# EFM32GG11B420F2048IL112 register map
File version: 4.0.0
CPU: CM4 r0p1, little endian, MPU, FPU, 3 interrupt priority bits
Registers are 32-bit, read-write, reset 0x0 unless marked. A register's access mark holds for its fields unless they carry their own. Offsets are from the block's base; [hi:lo] are bit positions; {n}, {i} and the like mark numbered series; 'fields as' and 'values as' point back to an identical list.

## EBI
Base 0x4000B000
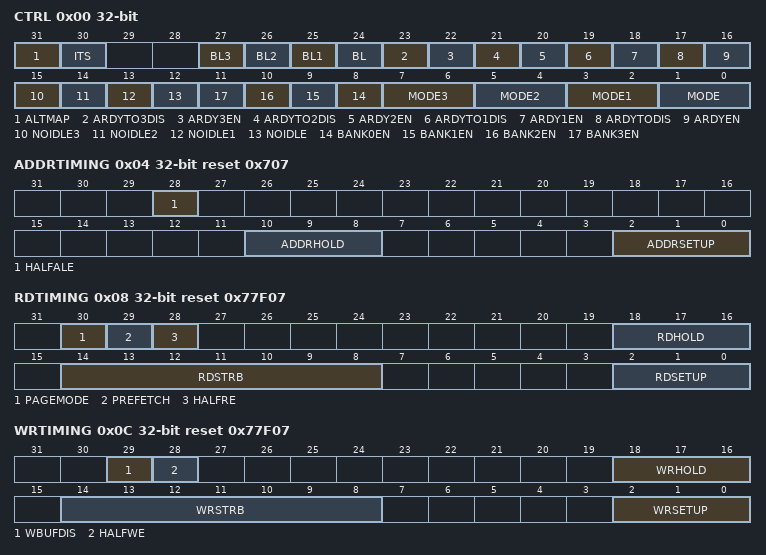
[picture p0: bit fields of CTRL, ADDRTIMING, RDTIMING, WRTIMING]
0x00 CTRL — Control Register
  [31] ALTMAP — Alternative Address Map Enable
  [30] ITS — Individual Timing Set, Line Polarity and Mode Definition Enable
  [27] BL3 — Byte Lane Enable for Bank 3
  [26] BL2 — Byte Lane Enable for Bank 2
  [25] BL1 — Byte Lane Enable for Bank 1
  [24] BL — Byte Lane Enable for Bank 0
  [23] ARDYTO3DIS — ARDY Timeout Disable for Bank 3
  [22] ARDY3EN — ARDY Enable for Bank 3
  [21] ARDYTO2DIS — ARDY Timeout Disable for Bank 2
  [20] ARDY2EN — ARDY Enable for Bank 2
  [19] ARDYTO1DIS — ARDY Timeout Disable for Bank 1
  [18] ARDY1EN — ARDY Enable for Bank 1
  [17] ARDYTODIS — ARDY Timeout Disable
  [16] ARDYEN — ARDY Enable
  [15] NOIDLE3 — No Idle Cycle Insertion on Bank 3
  [14] NOIDLE2 — No Idle Cycle Insertion on Bank 2
  [13] NOIDLE1 — No Idle Cycle Insertion on Bank 1
  [12] NOIDLE — No Idle Cycle Insertion on Bank 0
  [n+8] BANK{n}EN (n=0..3) — Bank {n} Enable
  [7:6] MODE3
    0=D8A8 (EBI_AD drives 8 bit data, 8 bit address, ALE not used. Extended address bits can be enabled.); 1=D16A16ALE (EBI_AD drives 16 bit data, 16 bit address, ALE is used for address latching. Extended address bits can be enabled.); 2=D8A24ALE (EBI_AD drives 8 bit data, 24 bit address, ALE is used for address latching. Extended address bits can be enabled.); 3=D16 (EBI_AD drives 16 bit data, ALE not used. Extended address bits can be enabled.)
  [5:4] MODE2
    values as MODE3
  [3:2] MODE1
    values as MODE3
  [1:0] MODE
    values as MODE3
0x04 ADDRTIMING reset 0x707 — Address Timing Register
  [28] HALFALE — Half Cycle ALE Strobe Duration Enable
  [10:8] ADDRHOLD — Address Hold Time
  [2:0] ADDRSETUP — Address Setup Time
0x08 RDTIMING reset 0x77F07 — Read Timing Register
  [30] PAGEMODE — Page Mode Access Enable
  [29] PREFETCH — Prefetch Enable
  [28] HALFRE — Half Cycle REn Strobe Duration Enable
  [18:16] RDHOLD — Read Hold Time
  [14:8] RDSTRB — Read Strobe Time
  [2:0] RDSETUP — Read Setup Time
0x0C WRTIMING reset 0x77F07 — Write Timing Register
  [29] WBUFDIS — Write Buffer Disable
  [28] HALFWE — Half Cycle WEn Strobe Duration Enable
  [18:16] WRHOLD — Write Hold Time
  [14:8] WRSTRB — Write Strobe Time
  [2:0] WRSETUP — Write Setup Time
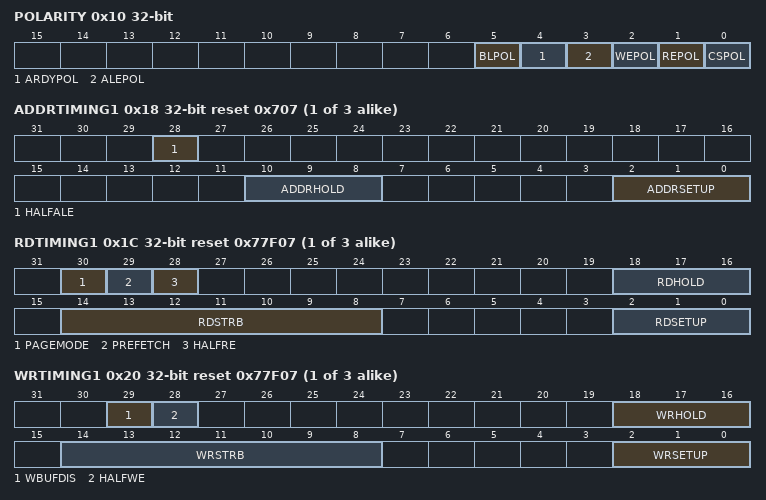
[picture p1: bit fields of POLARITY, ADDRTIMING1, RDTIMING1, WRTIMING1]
0x10 POLARITY
  [5] BLPOL — BL Polarity
  [4] ARDYPOL — ARDY Polarity
  [3] ALEPOL — Address Latch Polarity
  [2] WEPOL — Write Enable Polarity
  [1] REPOL — Read Enable Polarity
  [0] CSPOL — Chip Select Polarity
{0x8+0x10*i} ADDRTIMING{i} reset 0x707 (i=1..3) — Address Timing Register {i}
  fields as ADDRTIMING
{0xC+0x10*i} RDTIMING{i} reset 0x77F07 (i=1..3) — Read Timing Register {i}
  fields as RDTIMING
{0x10+0x10*i} WRTIMING{i} reset 0x77F07 (i=1..3) — Write Timing Register {i}
  fields as WRTIMING
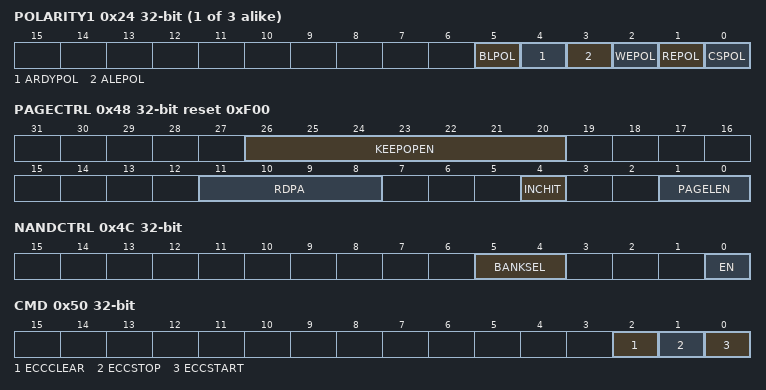
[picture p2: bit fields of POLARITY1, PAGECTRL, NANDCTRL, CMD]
{0x14+0x10*i} POLARITY{i} (i=1..3) — Polarity Register {i}
  fields as POLARITY
0x48 PAGECTRL reset 0xF00 — Page Control Register
  [26:20] KEEPOPEN — Maximum Page Open Time
  [11:8] RDPA — Page Read Access Time
  [4] INCHIT — Intrapage Hit Only on Incremental Addresses
  [1:0] PAGELEN — Page Length
    0=MEMBER4 (4 members in a page.); 1=MEMBER8 (8 members in a page.); 2=MEMBER16 (16 members in a page.); 3=MEMBER32 (32 members in a page.)
0x4C NANDCTRL — NAND Control Register
  [5:4] BANKSEL — NAND Flash Bank
    {v}=BANK{v} (Memory bank {v} is connected to a NAND Flash device.) (v=0..3)
  [0] EN — NAND Flash Control Enable
0x50 CMD wo — Command Register
  [2] ECCCLEAR — Error Correction Code Clear
  [1] ECCSTOP — Error Correction Code Generation Stop
  [0] ECCSTART — Error Correction Code Generation Start
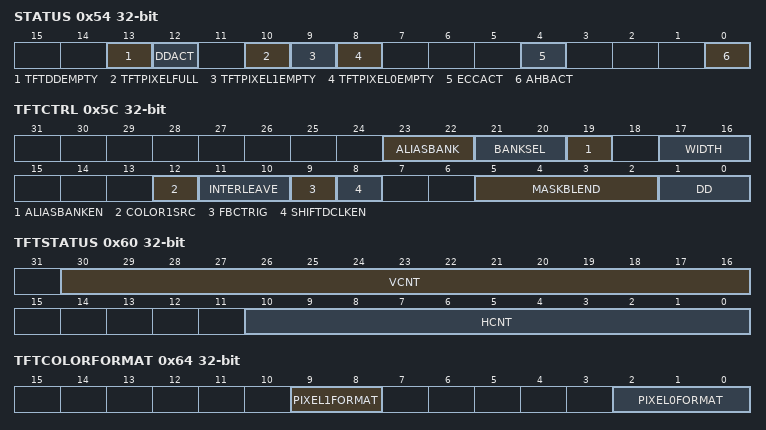
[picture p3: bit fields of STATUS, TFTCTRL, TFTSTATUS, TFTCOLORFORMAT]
0x54 STATUS ro
  [13] TFTDDEMPTY — EBI_TFTDD Register is Empty
  [12] DDACT — EBI Busy With Direct Drive Transactions
  [10] TFTPIXELFULL — EBI_TFTPIXEL0 is Full
  [9] TFTPIXEL1EMPTY — EBI_TFTPIXEL1 is Empty
  [8] TFTPIXEL0EMPTY — EBI_TFTPIXEL0 is Empty
  [4] ECCACT — EBI ECC Generation Active
  [0] AHBACT — EBI Busy With AHB Transaction
0x58 ECCPARITY ro
  [31:0] ECCPARITY — ECC Parity Data
0x5C TFTCTRL — TFT Control Register
  [23:22] ALIASBANK — Graphic Bank Select Aliasing
    {v}=Graphic Bank Select is alias to Bank Select {v} (v=0..3)
  [21:20] BANKSEL — Graphics Bank
    {v}=BANK{v} (Memory bank {v} is used for Direct Drive, Masking, and Alpha Blending.) (v=0..3)
  [19] ALIASBANKEN — Alias to Graphics Bank Enable
  [17:16] WIDTH — TFT Transaction Width
    0=BYTE (TFT Data is 8 bit wide.); 1=HALFWORD (TFT Data is 16 bit wide.)
  [12] COLOR1SRC — Masking/Alpha Blending Color1 Source
  [11:10] INTERLEAVE — Interleave Mode
    0=UNLIMITED (Allow unlimited interleaved EBI accesses per EBI_DCLK period. This can cause jitter on the EBI_DCLK); 1=ONEPERDCLK (Allow 1 interleaved EBI access per EBI_DCLK period.); 2=PORCH (Only allow EBI accesses during TFT porches.)
  [9] FBCTRIG — TFT Frame Base Copy Trigger
  [8] SHIFTDCLKEN — TFT EBI_DCLK Shift Enable
  [5:2] MASKBLEND — TFT Mask and Blend Mode
    0=DISABLED (Masking and Blending are disabled.); 1=IMASK (Internal Masking is enabled.); 2=IALPHA (Internal Alpha Blending is enabled.); 3=IMASKALPHA (Internal Masking and Alpha Blending are enabled.); 4=EFBMASK (External Frame Buffer Masking is enabled.); 5=EFBALPHA (External Frame Buffer Alpha Blending is enabled.); 6=EFBMASKALPHA (External Frame Buffer Masking and Alpha Blending are enabled.); 7=IFBMASK (Internal Frame Buffer Masking is enabled.); 8=IFBALPHA (Internal Frame Buffer Alpha Blending is enabled.); 9=IFBMASKALPHA (Internal Frame Buffer Masking and Alpha Blending are enabled.)
  [1:0] DD — TFT Direct Drive Mode
    0=DISABLED (Direct Drive is disabled.); 1=INTERNAL (Direct Drive from internal memory enabled and started.); 2=EXTERNAL (Direct Drive from external memory enabled and started.)
0x60 TFTSTATUS ro
  [30:16] VCNT — Vertical Count
  [10:0] HCNT — Horizontal Count
0x64 TFTCOLORFORMAT — Color Format Register
  [9:8] PIXEL1FORMAT — Source and Destination Pixel Color Format
    0=RGB555 (RGB data is 555); 1=RGB565 (RGB data is 565); 2=RGB666 (RGB data is 666); 3=RGB888 (RGB data is 888)
  [2:0] PIXEL0FORMAT — Sprite Pixel Color Format
    0=ARGB0555 (ARGB data is 0555); 1=ARGB0565 (ARGB data is 0565); 2=ARGB0666 (ARGB data is 0666); 3=ARGB0888 (ARGB data is 0888); 4=ARGB5555 (ARGB data is 5555); 5=ARGB6565 (ARGB data is 6565); 6=ARGB6666 (ARGB data is 6666); 7=ARGB8888 (ARGB data is 8888)
0x68 TFTFRAMEBASE
  [27:0] FRAMEBASE — Frame Base Address
0x70 TFTSTRIDE
  [11:0] HSTRIDE — Horizontal Stride
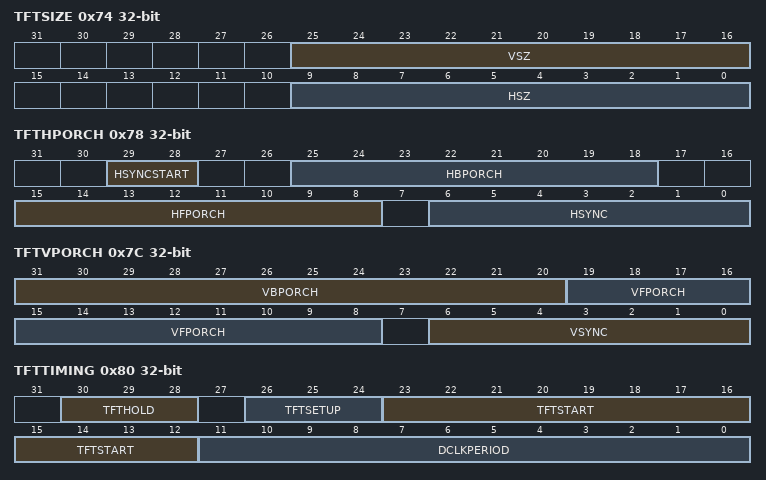
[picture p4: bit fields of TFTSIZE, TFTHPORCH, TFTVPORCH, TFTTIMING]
0x74 TFTSIZE
  [25:16] VSZ — Vertical Size (excluding Porches)
  [9:0] HSZ — Horizontal Size (excluding Porches)
0x78 TFTHPORCH — TFT Horizontal Porch Register
  [29:28] HSYNCSTART — HSYNC Start Delay
  [25:18] HBPORCH — Horizontal Back Porch Size
  [15:8] HFPORCH — Horizontal Front Porch Size
  [6:0] HSYNC — Horizontal Synchronization Pulse Width
0x7C TFTVPORCH — TFT Vertical Porch Register
  [31:20] VBPORCH — Vertical Back Porch Size
  [19:8] VFPORCH — Vertical Front Porch Size
  [6:0] VSYNC — Vertical Synchronization Pulse Width
0x80 TFTTIMING
  [30:28] TFTHOLD — TFT Hold Time
  [26:24] TFTSETUP — TFT Setup Time
  [23:12] TFTSTART — TFT Direct Drive Transaction Start
  [11:0] DCLKPERIOD — TFT Direct Drive Transaction (EBI_DCLK) Period
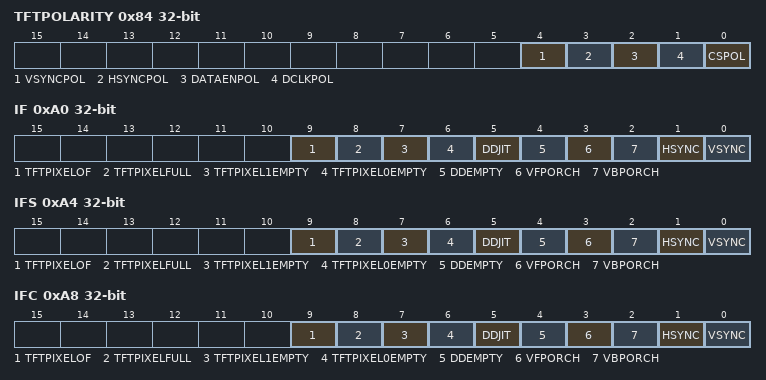
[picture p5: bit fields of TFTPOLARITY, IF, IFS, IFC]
0x84 TFTPOLARITY
  [4] VSYNCPOL — VSYNC Polarity
  [3] HSYNCPOL — Address Latch Polarity
  [2] DATAENPOL — TFT DATAEN Polarity
  [1] DCLKPOL — TFT DCLK Polarity
  [0] CSPOL — TFT Chip Select Polarity
0x88 TFTDD — TFT Direct Drive Data Register
  [23:0] DATA — TFT Direct Drive Data From Internal Memory
0x8C TFTALPHA — TFT Alpha Blending Register
  [8:0] ALPHA — TFT Alpha Blending Factor
0x90 TFTPIXEL0
  [23:0] DATA — RGB Data
0x94 TFTPIXEL1
  [23:0] DATA — RGB Data
0x98 TFTPIXEL ro — TFT Alpha Blending Result Pixel Register
  [23:0] DATA — Alpha Blending Result
0x9C TFTMASK — TFT Masking Register
  [23:0] TFTMASK — TFT Mask Value
0xA0 IF ro — Interrupt Flag Register
  [9] TFTPIXELOF — EBI_TFTPIXEL Register Overflow Interrupt Flag
  [8] TFTPIXELFULL — EBI_TFTPIXEL is Full Interrupt Flag
  [7] TFTPIXEL1EMPTY — EBI_TFTPIXEL1 is Empty Interrupt Flag
  [6] TFTPIXEL0EMPTY — EBI_TFTPIXEL0 is Empty Interrupt Flag
  [5] DDJIT — Direct Drive Jitter Interrupt Flag
  [4] DDEMPTY — Direct Drive Data Empty Interrupt Flag
  [3] VFPORCH — Vertical Front Porch Interrupt Flag
  [2] VBPORCH — Vertical Back Porch Interrupt Flag
  [1] HSYNC — Horizontal Sync Interrupt Flag
  [0] VSYNC — Vertical Sync Interrupt Flag
0xA4 IFS wo — Interrupt Flag Set Register
  [9] TFTPIXELOF — EBI_TFTPIXEL Overflow Interrupt Flag Set
  [8] TFTPIXELFULL — EBI_TFTPIXEL Full Interrupt Flag Set
  [7] TFTPIXEL1EMPTY — EBI_TFTPIXEL1 Empty Interrupt Flag Set
  [6] TFTPIXEL0EMPTY — EBI_TFTPIXEL0 Empty Interrupt Flag Set
  [5] DDJIT — Direct Drive Jitter Interrupt Flag Set
  [4] DDEMPTY — Direct Drive Data Empty Interrupt Flag Set
  [3] VFPORCH — Vertical Front Porch Interrupt Flag Set
  [2] VBPORCH — Vertical Back Porch Interrupt Flag Set
  [1] HSYNC — Horizontal Sync Interrupt Flag Set
  [0] VSYNC — Vertical Sync Interrupt Flag Set
0xA8 IFC wo — Interrupt Flag Clear Register
  [9] TFTPIXELOF — EBI_TFTPIXEL Overflow Interrupt Flag Clear
  [8] TFTPIXELFULL — EBI_TFTPIXEL Full Interrupt Flag Clear
  [7] TFTPIXEL1EMPTY — EBI_TFTPIXEL1 Empty Interrupt Flag Clear
  [6] TFTPIXEL0EMPTY — EBI_TFTPIXEL0 Empty Interrupt Flag Clear
  [5] DDJIT — Direct Drive Jitter Interrupt Flag Clear
  [4] DDEMPTY — Direct Drive Data Empty Interrupt Flag Clear
  [3] VFPORCH — Vertical Front Porch Interrupt Flag Clear
  [2] VBPORCH — Vertical Back Porch Interrupt Flag Clear
  [1] HSYNC — Horizontal Sync Interrupt Flag Clear
  [0] VSYNC — Vertical Sync Interrupt Flag Clear
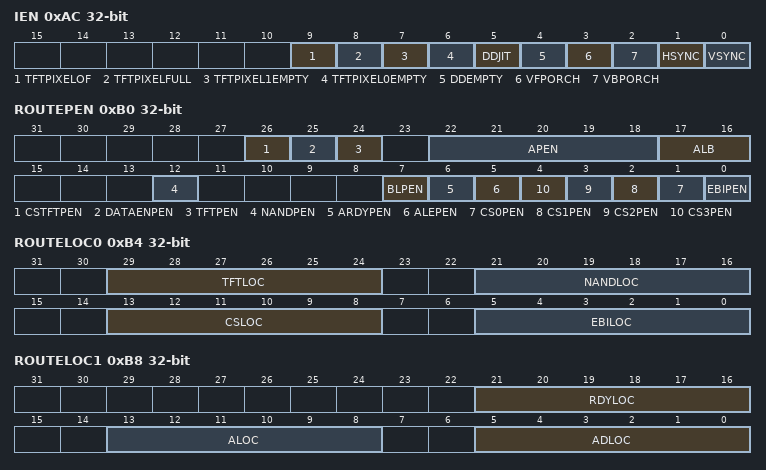
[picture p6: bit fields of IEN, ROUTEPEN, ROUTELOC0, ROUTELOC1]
0xAC IEN — Interrupt Enable Register
  [9] TFTPIXELOF — EBI_TFTPIXEL Overflow Interrupt Enable
  [8] TFTPIXELFULL — EBI_TFTPIXEL Full Interrupt Enable
  [7] TFTPIXEL1EMPTY — EBI_TFTPIXEL1 Empty Interrupt Enable
  [6] TFTPIXEL0EMPTY — EBI_TFTPIXEL0 Empty Interrupt Enable
  [5] DDJIT — Direct Drive Jitter Interrupt Enable
  [4] DDEMPTY — Direct Drive Data Empty Interrupt Enable
  [3] VFPORCH — Vertical Front Porch Interrupt Enable
  [2] VBPORCH — Vertical Back Porch Interrupt Enable
  [1] HSYNC — Horizontal Sync Interrupt Enable
  [0] VSYNC — Vertical Sync Interrupt Enable
0xB0 ROUTEPEN — I/O Routing Register
  [26] CSTFTPEN — EBI_CSTFT Pin Enable
  [25] DATAENPEN — EBI_DATA Pin Enable
  [24] TFTPEN — EBI_TFT Pin Enable
  [22:18] APEN — EBI_A Pin Enable
    0=A0 (All EBI_A pins are disabled.); {v}=A{v} (EBI_A[{v-1}:L] pins enabled.) (v=5..28)
  [17:16] ALB — Sets the Lower Bound for EBI_A Enabling
    0=A0 (Address lines from EBI_A[0] and upwards can be enabled via APEN.); 1=A8 (Address lines from EBI_A[8] and upwards can be enabled via APEN.); 2=A16 (Address lines from EBI_A[16] and upwards can be enabled via APEN.); 3=A24 (Address lines from EBI_A[24] and upwards can be enabled via APEN.)
  [12] NANDPEN — NANDRE and NANDWE Pin Enable
  [7] BLPEN — EBI_BL[1:0] Pin Enable
  [6] ARDYPEN — EBI_ARDY Pin Enable
  [5] ALEPEN — EBI_ALE Pin Enable
  [n+1] CS{n}PEN (n=0..3) — EBI_CS{n} Pin Enable
  [0] EBIPEN — EBI Pin Enable
0xB4 ROUTELOC0 — I/O Routing Location Register
  [29:24] TFTLOC — I/O Location
    {v}=LOC{v} (Location {v}) (v=0..3)
  [21:16] NANDLOC — I/O Location
    {v}=LOC{v} (Location {v}) (v=0..5)
  [13:8] CSLOC — I/O Location
    {v}=LOC{v} (Location {v}) (v=0..4)
  [5:0] EBILOC — I/O Location
    {v}=LOC{v} (Location {v}) (v=0..5)
0xB8 ROUTELOC1 — I/O Routing Location Register
  [21:16] RDYLOC — I/O Location
    {v}=LOC{v} (Location {v}) (v=0..5)
  [13:8] ALOC — I/O Location
    {v}=LOC{v} (Location {v}) (v=0..3)
  [5:0] ADLOC — I/O Location
    0=LOC0 (Location 0); 1=LOC1 (Location 1); 2=LOC2 (Location 2)

## Notices in the file
# License
Copyright 2021 Silicon Laboratories Inc. www.silabs.com
SPDX-License-Identifier: Zlib
The licensor of this software is Silicon Laboratories Inc.
This software is provided 'as-is', without any express or implied
warranty. In no event will the authors be held liable for any damages
arising from the use of this software.
Permission is granted to anyone to use this software for any purpose,
including commercial applications, and to alter it and redistribute it
freely, subject to the following restrictions:
1. The origin of this software must not be misrepresented; you must not
claim that you wrote the original software. If you use this software
in a product, an acknowledgment in the product documentation would be
appreciated but is not required.
2. Altered source versions must be plainly marked as such, and must not be
misrepresented as being the original software.
3. This notice may not be removed or altered from any source distribution.
